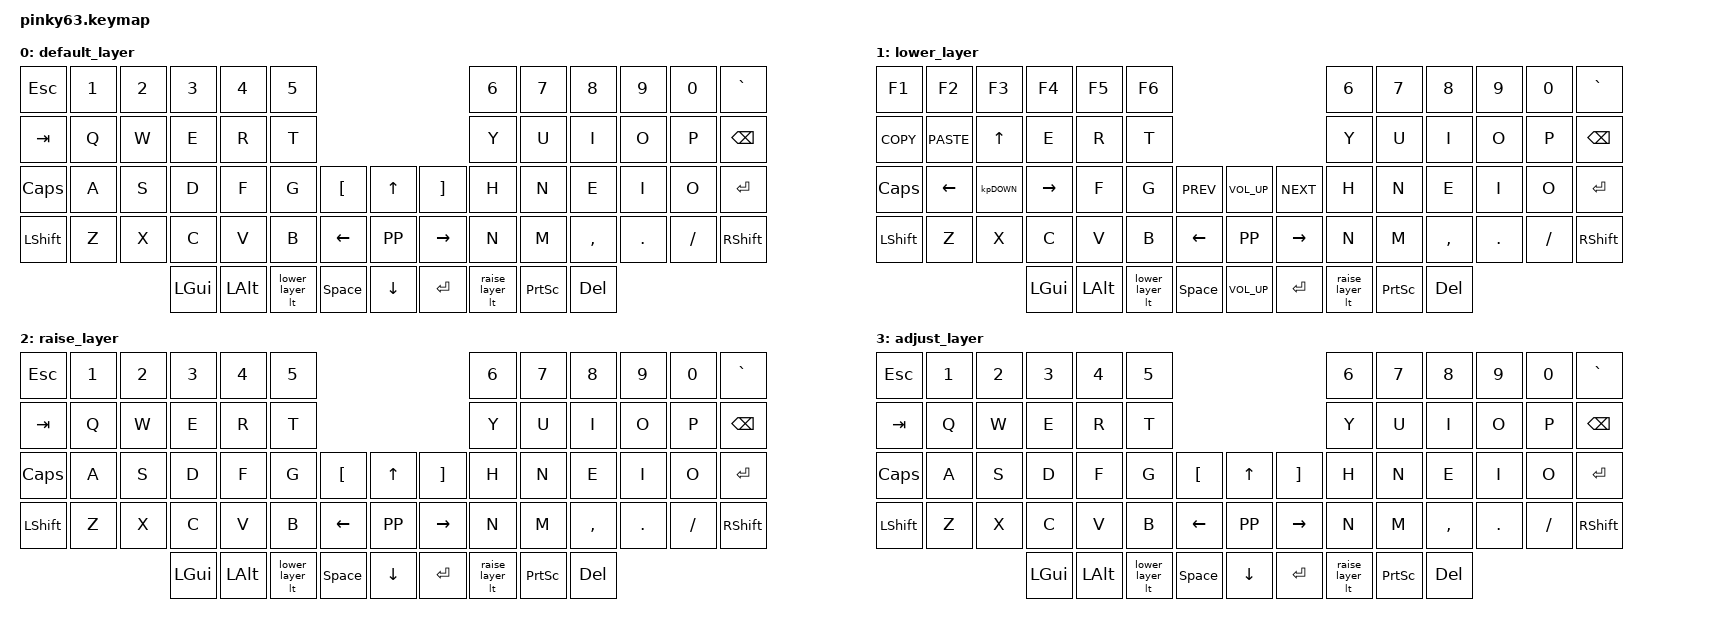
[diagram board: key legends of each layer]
/*
 * Copyright (c) 2020 The ZMK Contributors
 *
 * SPDX-License-Identifier: MIT
 */

#include <behaviors.dtsi>
#include <dt-bindings/zmk/keys.h>
#include <dt-bindings/zmk/bt.h>


#define default_layer 0
#define lower_layer 1
#define raise_layer 2
#define adjust_layer 3

/ {
        keymap {
                compatible = "zmk,keymap";

                default_layer {
// | Esc  |  1  |  2  |  3  |  4  |  5  |                    |  6  |  7   |  8  |  9  |  0  |    `      | 
// |  TAB |  Q  |  W  |  E  |  R  |  T  |                    |  Y  |  U   |  I  |  O  |  P  |   BSPC    |
// | SHFT |  A  |  S  |  D  |  F  |  G  | [   |  Up   |  ]   |  H  |  J   |  K  |  L  |  ;  |    '      |
// | CTRL |  Z  |  X  |  C  |  V  |  B  | LFT |  PP   |  RGT |  N  |  M   |  ,  |  .  |  /  | SHFT(RET) |
//                   |  WIN | ALT | LWR | SPC | DWN   |  ENT | RSE  | PSCRN | DEL |
                        bindings = <
   &kp ESC    &kp N1    &kp N2 &kp N3   &kp N4   &kp N5                                               &kp N6         &kp N7      &kp N8        &kp N9      &kp N0          &kp GRAVE
   &kp TAB    &kp Q     &kp W  &kp E    &kp R    &kp T                                                &kp Y          &kp U       &kp I         &kp O       &kp P   	   &kp BACKSPACE
   &kp CAPS   &kp A     &kp S  &kp D    &kp F    &kp G     &kp LBKT        &kp UP    &kp RBKT         &kp H          &kp N       &kp E         &kp I       &kp O           &kp ENTER
   &kp LSHIFT &kp Z  	&kp X  &kp C    &kp V    &kp B     &kp LEFT        &kp K_PP  &kp RIGHT        &kp N          &kp M       &kp COMMA     &kp PERIOD  &kp FSLH 	   &kp RSHFT
                              &kp LGUI   &kp LALT  &lt lower_layer &kp Space &kp DOWN  &kp ENTER &lt raise_layer &kp PSCRN &kp DEL
                        >;
                };

                lower_layer {
// | F1   |  F2     |  F3 |  F4 |  F5 | F6  |                    |  F7 |  F8  |  F9 | F10 | F11 |  F12  | 
// | Copy |  PASTE  |  UP  |  E  |  R  |  T  |                    |  Y  |  U   |  I  |  O  |  P  |   BSPC    |
// | CAPS |  LFT    |  DWN  |  RGT  |  F  |  G  | [   |  Up   |  ]   |  H  |  J   |  K  |  L  |  ;  |    '      |
// | CTRL |  Z      |  X  |  C  |  V  |  B  | LFT |  PP   |  RGT |  N  |  M   |  ,  |  .  |  /  | SHFT(RET) |
//                      |  WIN | ALT | LWR | SPC | DWN   |  ENT | RSE  | PSCRN | DEL |
                        bindings = <
   &kp F1    &kp F2    &kp F3 &kp F4   &kp F5   &kp F6                                               &kp N6         &kp N7      &kp N8        &kp N9      &kp N0          &kp GRAVE
   &kp K_COPY   &kp K_PASTE     &kp UP  &kp E    &kp R    &kp T                                                &kp Y          &kp U       &kp I         &kp O       &kp P   	   &kp BACKSPACE
   &kp CAPS   &kp LEFT     &kpDOWN  &kp RIGHT    &kp F    &kp G     &kp K_PREV        &kp K_VOL_UP    &kp K_NEXT         &kp H          &kp N       &kp E         &kp I       &kp O           &kp ENTER
   &kp LSHIFT &kp Z  	&kp X  &kp C    &kp V    &kp B     &kp LEFT        &kp K_PP  &kp RIGHT        &kp N          &kp M       &kp COMMA     &kp PERIOD  &kp FSLH 	   &kp RSHFT
                              &kp LGUI   &kp LALT  &lt lower_layer &kp Space &kp K_VOL_UP  &kp ENTER &lt raise_layer &kp PSCRN &kp DEL
                        >;
                };

                raise_layer {
// | Esc  |  1  |  2  |  3  |  4  |  5  |                    |  6  |  7   |  8  |  9  |  0  |    `      | 
// |  TAB |  Q  |  W  |  E  |  R  |  T  |                    |  Y  |  U   |  I  |  O  |  P  |   BSPC    |
// | SHFT |  A  |  S  |  D  |  F  |  G  | [   |  Up   |  ]   |  H  |  J   |  K  |  L  |  ;  |    '      |
// | CTRL |  Z  |  X  |  C  |  V  |  B  | LFT |  PP   |  RGT |  N  |  M   |  ,  |  .  |  /  | SHFT(RET) |
//                   |  WIN | ALT | LWR | SPC | DWN   |  ENT | RSE  | PSCRN | DEL |
                        bindings = <
   &kp ESC    &kp N1    &kp N2 &kp N3   &kp N4   &kp N5                                               &kp N6         &kp N7      &kp N8        &kp N9      &kp N0          &kp GRAVE
   &kp TAB    &kp Q     &kp W  &kp E    &kp R    &kp T                                                &kp Y          &kp U       &kp I         &kp O       &kp P   	   &kp BACKSPACE
   &kp CAPS   &kp A     &kp S  &kp D    &kp F    &kp G     &kp LBKT        &kp UP    &kp RBKT         &kp H          &kp N       &kp E         &kp I       &kp O           &kp ENTER
   &kp LSHIFT &kp Z  	&kp X  &kp C    &kp V    &kp B     &kp LEFT        &kp K_PP  &kp RIGHT        &kp N          &kp M       &kp COMMA     &kp PERIOD  &kp FSLH 	   &kp RSHFT
                              &kp LGUI   &kp LALT  &lt lower_layer &kp Space &kp DOWN  &kp ENTER &lt raise_layer &kp PSCRN &kp DEL
                        >;
                };

                adjust_layer {
// | Esc  |  1  |  2  |  3  |  4  |  5  |                    |  6  |  7   |  8  |  9  |  0  |    `      | 
// |  TAB |  Q  |  W  |  E  |  R  |  T  |                    |  Y  |  U   |  I  |  O  |  P  |   BSPC    |
// | SHFT |  A  |  S  |  D  |  F  |  G  | [   |  Up   |  ]   |  H  |  J   |  K  |  L  |  ;  |    '      |
// | CTRL |  Z  |  X  |  C  |  V  |  B  | LFT |  PP   |  RGT |  N  |  M   |  ,  |  .  |  /  | SHFT(RET) |
//                   |  WIN | ALT | LWR | SPC | DWN   |  ENT | RSE  | PSCRN | DEL |
                        bindings = <
   &kp ESC    &kp N1    &kp N2 &kp N3   &kp N4   &kp N5                                               &kp N6         &kp N7      &kp N8        &kp N9      &kp N0          &kp GRAVE
   &kp TAB    &kp Q     &kp W  &kp E    &kp R    &kp T                                                &kp Y          &kp U       &kp I         &kp O       &kp P   	   &kp BACKSPACE
   &kp CAPS   &kp A     &kp S  &kp D    &kp F    &kp G     &kp LBKT        &kp UP    &kp RBKT         &kp H          &kp N       &kp E         &kp I       &kp O           &kp ENTER
   &kp LSHIFT &kp Z  	&kp X  &kp C    &kp V    &kp B     &kp LEFT        &kp K_PP  &kp RIGHT        &kp N          &kp M       &kp COMMA     &kp PERIOD  &kp FSLH 	   &kp RSHFT
                              &kp LGUI   &kp LALT  &lt lower_layer &kp Space &kp DOWN  &kp ENTER &lt raise_layer &kp PSCRN &kp DEL
                        >;
                };
        };
};
